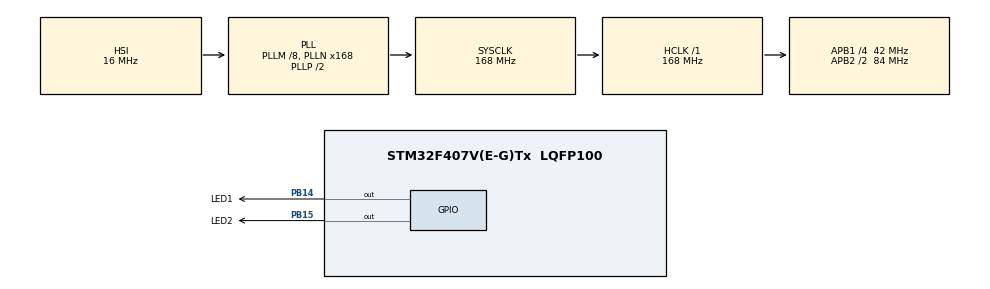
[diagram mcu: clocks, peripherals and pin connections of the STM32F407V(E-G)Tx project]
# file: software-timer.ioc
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Mcu.Family=STM32F4
Mcu.Name=STM32F407V(E-G)Tx
Mcu.Package=LQFP100
NVIC.PriorityGroup=NVIC_PRIORITYGROUP_4
NVIC.TIM6_DAC_IRQn=true\:0\:0\:false\:false\:true\:true\:true
PA13.Mode=Serial_Wire
PA13.Signal=SYS_JTMS-SWDIO
PA14.Mode=Serial_Wire
PA14.Signal=SYS_JTCK-SWCLK
PB14.GPIO_Label=LED1
PB14.Signal=GPIO_Output
PB15.GPIO_Label=LED2
PB15.Signal=GPIO_Output
ProjectManager.HeapSize=0x200
ProjectManager.StackSize=0x400
ProjectManager.TargetToolchain=MDK-ARM V5.27
RCC.48MHZClocksFreq_Value=84000000
RCC.AHBFreq_Value=168000000
RCC.APB1CLKDivider=RCC_HCLK_DIV4
RCC.APB1Freq_Value=42000000
RCC.APB1TimFreq_Value=84000000
RCC.APB2CLKDivider=RCC_HCLK_DIV2
RCC.APB2Freq_Value=84000000
RCC.APB2TimFreq_Value=168000000
RCC.CortexFreq_Value=168000000
RCC.HCLKFreq_Value=168000000
RCC.HSE_VALUE=25000000
RCC.HSI_VALUE=16000000
RCC.LSE_VALUE=32768
RCC.PLLM=8
RCC.PLLN=168
RCC.SYSCLKFreq_VALUE=168000000
RCC.SYSCLKSource=RCC_SYSCLKSOURCE_PLLCLK
RCC.VCOOutputFreq_Value=336000000
VP_TIM6_VS_ClockSourceINT.Mode=Enable_Timer
board=custom

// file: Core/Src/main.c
/* USER CODE BEGIN Header */
/**
  ******************************************************************************
  * @file           : main.c
  * @brief          : Main program body
  ******************************************************************************
  * @attention
  *
  * <h2><center>&copy; Copyright (c) 2021 STMicroelectronics.
  * All rights reserved.</center></h2>
  *
  * This software component is licensed by ST under BSD 3-Clause license,
  * the "License"; You may not use this file except in compliance with the
  * License. You may obtain a copy of the License at:
  *                        opensource.org/licenses/BSD-3-Clause
  *
  ******************************************************************************
  */
/* USER CODE END Header */
#include "main.h"
#include "tim.h"
#include "gpio.h"

/* USER CODE BEGIN PM */

typedef void callback(void);

typedef struct softTimer {
 uint8_t state; //state
 uint8_t mode; //mode
 uint32_t match; //expiration time
 uint32_t period; // timing period
 callback *cb; //callback function pointer
}softTimer;

typedef enum tmrState {
 SOFT_TIMER_STOPPED = 0, //stop
 SOFT_TIMER_RUNNING, //Run
 SOFT_TIMER_TIMEOUT // timeout
}tmrState;

typedef enum tmrMode {
 MODE_ONE_SHOT = 0, // single mode
 MODE_PERIODIC, //cycle mode
}tmrMode;

#define TIMER_NUM 2

static softTimer timer[TIMER_NUM]; //software timer array

void softTimer_Init(void)
{
		uint16_t i;

		for(i=0; i<TIMER_NUM; i++)
		{
				timer[i].state = SOFT_TIMER_STOPPED;
				timer[i].mode = MODE_ONE_SHOT;
				timer[i].match = 0;
				timer[i].period = 0;
				timer[i].cb = NULL;
		}
}

void softTimer_Start(uint16_t id, tmrMode mode, uint32_t delay, callback *cb)
{
    timer[id].match = HAL_GetTick() + delay;
    timer[id].period = delay;
    timer[id].state = SOFT_TIMER_RUNNING;
    timer[id].mode = mode;
    timer[id].cb = cb;
}

void softTimer_Stop(uint16_t id)
{
    assert_param(id < TIMER_NUM);
    timer[id].state = SOFT_TIMER_STOPPED;
}

uint8_t softTimer_GetState(uint16_t id)
{
    return timer[id].state;
}

void softTimer_Update(void)
{
    uint16_t i;

    for(i=0; i<TIMER_NUM; i++) {
      switch (timer[i].state) {
          case SOFT_TIMER_STOPPED:
              break;

          case SOFT_TIMER_RUNNING:
              if(timer[i].match <= HAL_GetTick())
							{
                  timer[i].state = SOFT_TIMER_TIMEOUT;
									timer[i].cb(); //Execute callback function
              }
              break;

          case SOFT_TIMER_TIMEOUT:
              if(timer[i].mode == MODE_ONE_SHOT) {
                  timer[i].state = SOFT_TIMER_STOPPED;
              } else {
                  timer[i].match = HAL_GetTick() + timer[i].period;
                  timer[i].state = SOFT_TIMER_RUNNING;
              }
              break;

          default:
              break;
      }
  }

}

void HAL_TIM_PeriodElapsedCallback(TIM_HandleTypeDef *htim)
{
    if(htim->Instance == TIM6)
    {
        softTimer_Update();
    }
}

void LED1_Blink(void)
{
	HAL_GPIO_TogglePin(LED1_GPIO_Port,LED1_Pin);
}

void LED2_Blink(void)
{
	HAL_GPIO_TogglePin(LED2_GPIO_Port,LED2_Pin);
}
/* USER CODE END PM */

void SystemClock_Config(void);

int main(void)
{

  /* MCU Configuration--------------------------------------------------------*/

  /* Reset of all peripherals, Initializes the Flash interface and the Systick. */
  HAL_Init();

  /* Configure the system clock */
  SystemClock_Config();

  /* Initialize all configured peripherals */
  MX_GPIO_Init();
  MX_TIM6_Init();
  /* USER CODE BEGIN 2 */

	softTimer_Start(0, MODE_PERIODIC, 1000, LED1_Blink);
	softTimer_Start(1, MODE_PERIODIC, 100,  LED2_Blink);

  HAL_TIM_Base_Start_IT(&htim6);
  /* USER CODE END 2 */

  /* Infinite loop */
  while (1)
  {

    /* USER CODE BEGIN 3 */
		 //softTimer_Update();
		 //HAL_Delay(50);

  }
  /* USER CODE END 3 */
}

void SystemClock_Config(void)
{
  RCC_OscInitTypeDef RCC_OscInitStruct = {0};
  RCC_ClkInitTypeDef RCC_ClkInitStruct = {0};

  /** Configure the main internal regulator output voltage
  */
  __HAL_RCC_PWR_CLK_ENABLE();
  __HAL_PWR_VOLTAGESCALING_CONFIG(PWR_REGULATOR_VOLTAGE_SCALE1);
  /** Initializes the RCC Oscillators according to the specified parameters
  * in the RCC_OscInitTypeDef structure.
  */
  RCC_OscInitStruct.OscillatorType = RCC_OSCILLATORTYPE_HSI;
  RCC_OscInitStruct.HSIState = RCC_HSI_ON;
  RCC_OscInitStruct.HSICalibrationValue = RCC_HSICALIBRATION_DEFAULT;
  RCC_OscInitStruct.PLL.PLLState = RCC_PLL_ON;
  RCC_OscInitStruct.PLL.PLLSource = RCC_PLLSOURCE_HSI;
  RCC_OscInitStruct.PLL.PLLM = 8;
  RCC_OscInitStruct.PLL.PLLN = 168;
  RCC_OscInitStruct.PLL.PLLP = RCC_PLLP_DIV2;
  RCC_OscInitStruct.PLL.PLLQ = 4;
  if (HAL_RCC_OscConfig(&RCC_OscInitStruct) != HAL_OK)
  {
    Error_Handler();
  }
  /** Initializes the CPU, AHB and APB buses clocks
  */
  RCC_ClkInitStruct.ClockType = RCC_CLOCKTYPE_HCLK|RCC_CLOCKTYPE_SYSCLK
                              |RCC_CLOCKTYPE_PCLK1|RCC_CLOCKTYPE_PCLK2;
  RCC_ClkInitStruct.SYSCLKSource = RCC_SYSCLKSOURCE_PLLCLK;
  RCC_ClkInitStruct.AHBCLKDivider = RCC_SYSCLK_DIV1;
  RCC_ClkInitStruct.APB1CLKDivider = RCC_HCLK_DIV4;
  RCC_ClkInitStruct.APB2CLKDivider = RCC_HCLK_DIV2;

  if (HAL_RCC_ClockConfig(&RCC_ClkInitStruct, FLASH_LATENCY_5) != HAL_OK)
  {
    Error_Handler();
  }
}

void Error_Handler(void)
{
  __disable_irq();
  while (1)
  {
  }
}

/************************ (C) COPYRIGHT STMicroelectronics *****END OF FILE****/
